# RTS5921 register map
Vendor: Realtek Semiconductor Corp.; Series: RTS5921 Series; File version: 0.01
CPU: ARMV8MBL r0p0, little endian, MPU, no FPU, VTOR, 3 interrupt priority bits
Registers are 32-bit, read-write, reset 0x0 unless marked. A register's access mark holds for its fields unless they carry their own. Offsets are from the block's base; [hi:lo] are bit positions; {n}, {i} and the like mark numbered series.

## RCCAL — RC Calibration Controller
Base 0x40100100
0x00 CTRLR0 — Control Register 0
0x04 RC25RESULT — RC25M Result Register
0x08 RC32RESULT — RC32K Result Register
0x0C RCDIFF — RC25M/RC32K Diff Register
0x10 RC25CTRL — RC25M Analog Control Register
0x14 RC32CTRL — RC32K Analog Control Register

## ADC — SAR ADC Controller
Base 0x40100800
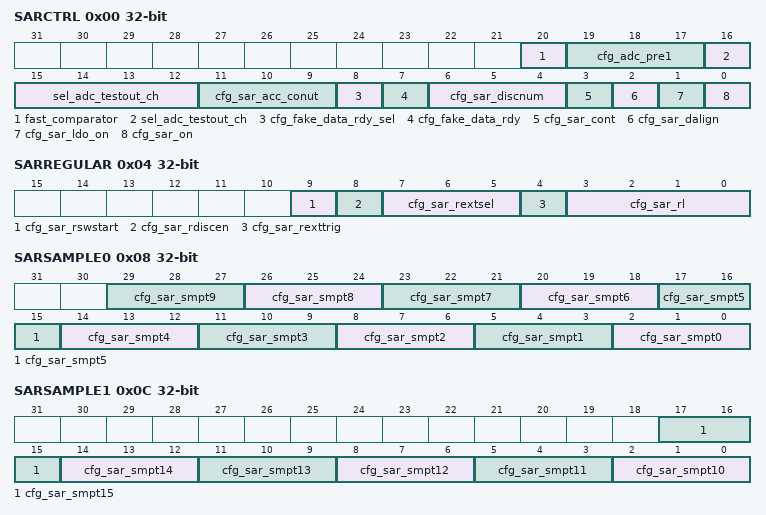
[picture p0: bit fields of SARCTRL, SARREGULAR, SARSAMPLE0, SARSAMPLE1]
0x00 SARCTRL
  [20] fast_comparator — nan
  [19:17] cfg_adc_pre1 — nan
  [16:12] sel_adc_testout_ch — nan
  [11:9] cfg_sar_acc_conut — nan
  [8] cfg_fake_data_rdy_sel — nan
  [7] cfg_fake_data_rdy — nan
  [6:4] cfg_sar_discnum — nan
  [3] cfg_sar_cont — nan
  [2] cfg_sar_dalign — nan
  [1] cfg_sar_ldo_on — nan
  [0] cfg_sar_on — nan
0x04 SARREGULAR
  [9] cfg_sar_rswstart — nan
  [8] cfg_sar_rdiscen — nan
  [7:5] cfg_sar_rextsel — nan
  [4] cfg_sar_rexttrig — nan
  [3:0] cfg_sar_rl — nan
0x08 SARSAMPLE0
  [3n+2:3n] cfg_sar_smpt{n} (n=0..9) — nan
0x0C SARSAMPLE1
  [3n-28:3n-30] cfg_sar_smpt{n} (n=10..15) — nan
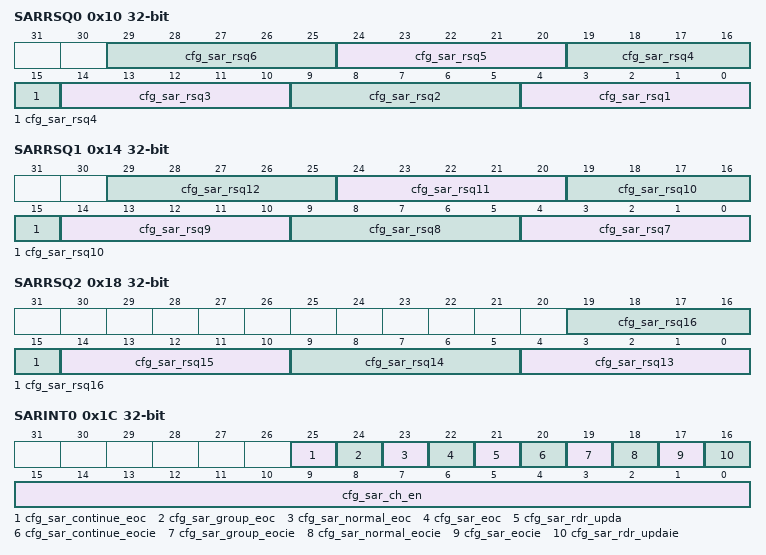
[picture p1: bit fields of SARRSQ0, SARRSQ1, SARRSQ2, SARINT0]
0x10 SARRSQ0
  [5n-1:5n-5] cfg_sar_rsq{n} (n=1..6) — nan
0x14 SARRSQ1
  [5n-31:5n-35] cfg_sar_rsq{n} (n=7..12) — nan
0x18 SARRSQ2
  [5n-61:5n-65] cfg_sar_rsq{n} (n=13..16) — nan
0x1C SARINT0
  [25] cfg_sar_continue_eoc — nan
  [24] cfg_sar_group_eoc — nan
  [23] cfg_sar_normal_eoc — nan
  [22] cfg_sar_eoc — nan
  [21] cfg_sar_rdr_upda — nan
  [20] cfg_sar_continue_eocie — nan
  [19] cfg_sar_group_eocie — nan
  [18] cfg_sar_normal_eocie — nan
  [17] cfg_sar_eocie — nan
  [16] cfg_sar_rdr_updaie — nan
  [15:0] cfg_sar_ch_en — nan
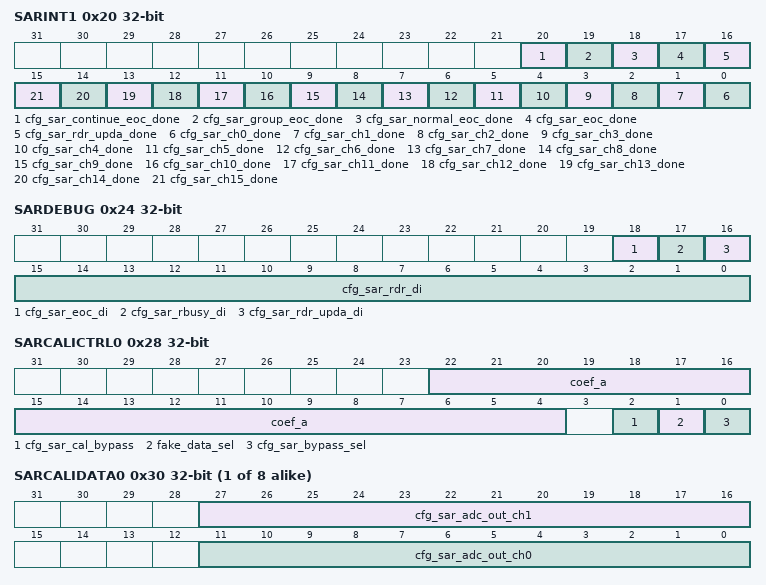
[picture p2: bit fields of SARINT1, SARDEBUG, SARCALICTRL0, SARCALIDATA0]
0x20 SARINT1
  [20] cfg_sar_continue_eoc_done — nan
  [19] cfg_sar_group_eoc_done — nan
  [18] cfg_sar_normal_eoc_done — nan
  [17] cfg_sar_eoc_done — nan
  [16] cfg_sar_rdr_upda_done — nan
  [n] cfg_sar_ch{n}_done (n=0..15) — nan
0x24 SARDEBUG
  [18] cfg_sar_eoc_di ro — nan
  [17] cfg_sar_rbusy_di ro — nan
  [16] cfg_sar_rdr_upda_di ro — nan
  [15:0] cfg_sar_rdr_di ro — nan
0x28 SARCALICTRL0
  [22:4] coef_a ro — nan
  [2] cfg_sar_cal_bypass ro — nan
  [1] fake_data_sel ro — nan
  [0] cfg_sar_bypass_sel ro — nan
0x2C SARCALICTRL1
  [26:0] coef_b ro — nan
{0x30+4i} SARCALIDATA{i} (i=0..7)
  [27:16] cfg_sar_adc_out_ch{2i+1} ro — nan
  [11:0] cfg_sar_adc_out_ch{2i} ro — nan
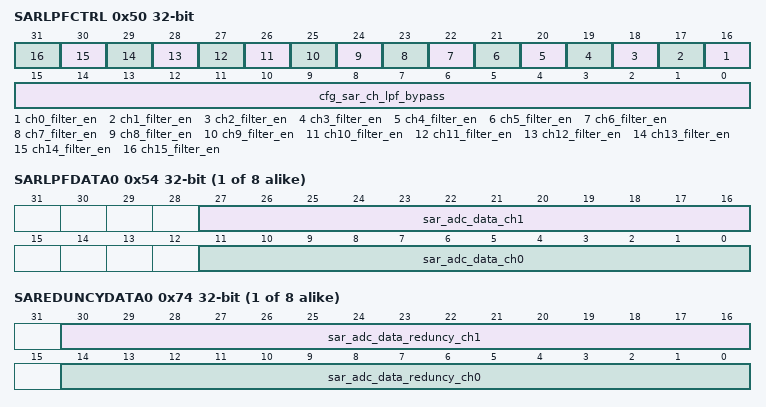
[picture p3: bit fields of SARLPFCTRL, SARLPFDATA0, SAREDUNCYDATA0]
0x50 SARLPFCTRL
  [n+16] ch{n}_filter_en (n=0..15) — nan
  [15:0] cfg_sar_ch_lpf_bypass — nan
{0x54+4i} SARLPFDATA{i} (i=0..7)
  [27:16] sar_adc_data_ch{2i+1} ro — nan
  [11:0] sar_adc_data_ch{2i} ro — nan
{0x74+4i} SAREDUNCYDATA{i} (i=0..7)
  [30:16] sar_adc_data_reduncy_ch{2i+1} ro — nan
  [14:0] sar_adc_data_reduncy_ch{2i} ro — nan

## TACHO0 — Tachometer Controller
Base 0x40100900
Same registers: TACHO1 0x40100920, TACHO2 0x40100940, TACHO3 0x40100960
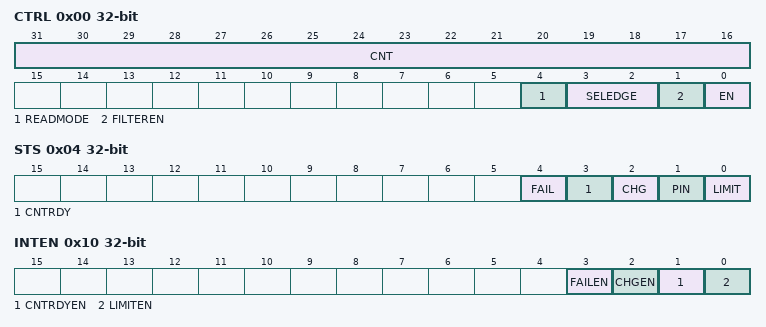
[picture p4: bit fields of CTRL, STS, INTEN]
0x00 CTRL — CONTROL REGISTER
  [31:16] CNT ro — Counter of Tachometer
  [4] READMODE — Select Reading Mode of Tachometer
    0=LOW_TO_HIGH (Counter is incremented when input transitions from low-to-high); 1=RISING_EDGE (Counter is incremented on the rising edge of the 100KHz input)
  [3:2] SELEDGE — Select Edges of Tachometer
    0=x2 (x2 edges (1/2 TACH period)); 1=x3 (x3 edges (1/2 TACH period)); 2=x5 (x5 edges (2 TACH period)); 3=x9 (x9 edges (4 TACH period))
  [1] FILTEREN — Enable Filter of Tachometer
    0=DISABLE (Disabled filter); 1=ENABLE (Enabled filter)
  [0] EN — Enable Tachometer Controller
    0=DISABLE (Disable tachometer controller); 1=ENABLE (Enabled tachometer controller)
0x04 STS — STATUS REGISTER
  [4] FAIL — Status of Count Ready
    0=NO_FAIL (Tachometer is not fail); 1=FAIL (Tachometer is fail)
  [3] CNTRDY — Status of Count Ready
    0=NOT_READY (Tachometer is not ready to count); 1=READY (Tachometer is ready to count)
  [2] CHG — Tachometer Input Changes Its Status
    0=STABLE (Tachometer input status is stable); 1=CHANGED (Tachometer input status is changed)
  [1] PIN ro — Pin Status of Tachometer
    0=LOW (Tachometer input pin is low); 1=HIGH (Tachometer input pin is high)
  [0] LIMIT — Limit status of Tachometer
    0=WITHIN (Counter is within limit); 1=OUTSIDE (Counter is outside of limit)
0x08 LIMITH — HIGH-LIMIT REGISTER
  [15:0] VAL — High limit value
0x0C LIMITL — LOW-LIMIT REGISTER
  [15:0] VAL — Low limit value
0x10 INTEN — INTERRUPT ENABLE REGISTER
  [3] FAILEN — Fail Interrupt Enable
    0=DISABLE (Disabled fail interrupt); 1=ENABLE (Enabled fail interrupt)
  [2] CHGEN — Input Change Interrupt Enable
    0=DISABLE (Disabled input change interrupt); 1=ENABLE (Enabled input change interrupt)
  [1] CNTRDYEN — Ready to count Interrupt Enable
    0=DISABLE (Disabled ready to count interrupt); 1=ENABLE (Enabled ready to count interrupt)
  [0] LIMITEN — Limit Interrupt Enable
    0=DISABLE (Disabled limit interrupt); 1=ENABLE (Enabled limit interrupt)
0x14 THRESHOLD
0x18 TIMEOUT
